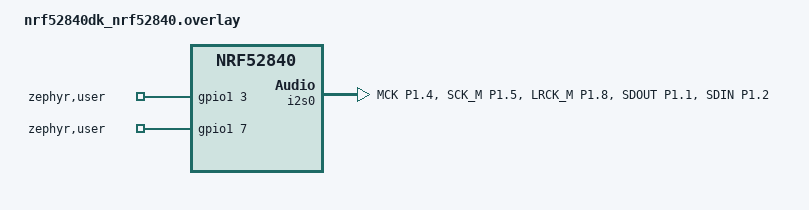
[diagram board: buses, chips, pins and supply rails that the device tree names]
/*
 * Copyright (c) 2025 Nordic Semiconductor ASA
 *
 * SPDX-License-Identifier: LicenseRef-Nordic-5-Clause
 */

/ {
	aliases {
		i2s-node0 = &i2s0;
	};

	zephyr,user {
		gpios = <&gpio1 3 GPIO_ACTIVE_HIGH>,  /* Connect with I2C_MCK */
			<&gpio1 7 GPIO_ACTIVE_HIGH>;  /* Connect with I2S_LRCK_M */
	};
};

&pinctrl {
	i2s0_default_alt: i2s0_default_alt {
		group1 {
			psels = <NRF_PSEL(I2S_MCK, 1, 4)>,
				<NRF_PSEL(I2S_SCK_M, 1, 5)>,
				<NRF_PSEL(I2S_LRCK_M, 1, 8)>,
				<NRF_PSEL(I2S_SDOUT, 1, 1)>,  /* I2S_SDOUT shorted to I2S_SDIN */
				<NRF_PSEL(I2S_SDIN, 1, 2)>;
		};
	};
};

&i2s0 {
	status = "okay";
	pinctrl-0 = <&i2s0_default_alt>;
	pinctrl-names = "default";
};
